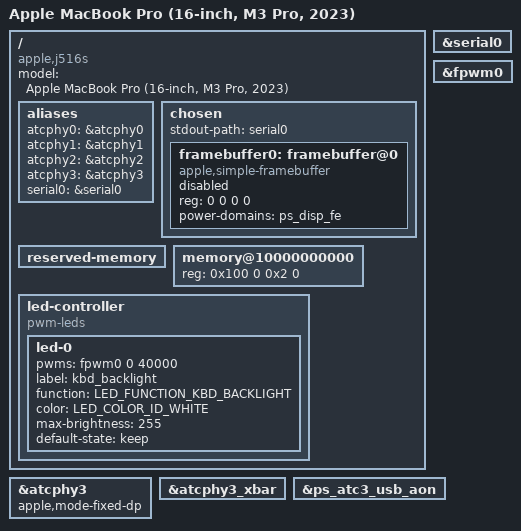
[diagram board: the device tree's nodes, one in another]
// SPDX-License-Identifier: GPL-2.0+ OR MIT
/*
 * MacBook Pro (16-inch, M3 Pro, 2023)
 *
 * target-type: J516s
 *
 * Copyright The Asahi Linux Contributors
 */

/dts-v1/;

#include <dt-bindings/leds/common.h>

#include "t6030.dtsi"

/ {
	compatible = "apple,j516s", "apple,t6030", "apple,arm-platform";
	model = "Apple MacBook Pro (16-inch, M3 Pro, 2023)";

	aliases {
		atcphy0 = &atcphy0;
		atcphy1 = &atcphy1;
		atcphy2 = &atcphy2;
		atcphy3 = &atcphy3;
		serial0 = &serial0;
	};

	chosen {
		#address-cells = <2>;
		#size-cells = <2>;
		ranges;

		stdout-path = "serial0";

		framebuffer0: framebuffer@0 {
			compatible = "apple,simple-framebuffer", "simple-framebuffer";
			reg = <0 0 0 0>; /* To be filled by loader */
			/* Format properties will be added by loader */
			status = "disabled";
			power-domains = <&ps_disp_fe>;
			//panel = &panel; FIXME
		};
	};

	reserved-memory {
		#address-cells = <2>;
		#size-cells = <2>;
		ranges;
		/* To be filled by loader */
	};

	memory@10000000000 {
		device_type = "memory";
		reg = <0x100 0 0x2 0>; /* To be filled by loader */
	};

	led-controller {
		compatible = "pwm-leds";
		led-0 {
			pwms = <&fpwm0 0 40000>;
			label = "kbd_backlight";
			function = LED_FUNCTION_KBD_BACKLIGHT;
			color = <LED_COLOR_ID_WHITE>;
			max-brightness = <255>;
			default-state = "keep";
		};
	};
};

&serial0 {
	status = "okay";
};

&fpwm0 {
	status = "okay";
};

&atcphy3 {
	apple,mode-fixed-dp;
};

&atcphy3_xbar {
	status = "okay";
};

// TODO: USB-C controller

// Disabled for now since t6030 doesn't include those nodes...
// enable once generalized to other SoCs that have USB on ATC3
#if 0
/* ATC3 is used for DisplayPort -> HDMI only */
&dwc3_3_dart_0 {
	status = "disabled";
};

&dwc3_3_dart_1 {
	status = "disabled";
};

&dwc3_3 {
	status = "disabled";
};
/* Delete unused dwc3_3 to prevent dt_disable_missing_devs() from disabling
 * atcphy3 via phandle references from a disablecd device.
 */
/delete-node/ &dwc3_3;
#endif

&ps_atc3_usb_aon {
	/delete-property/ apple,always-on;
};
